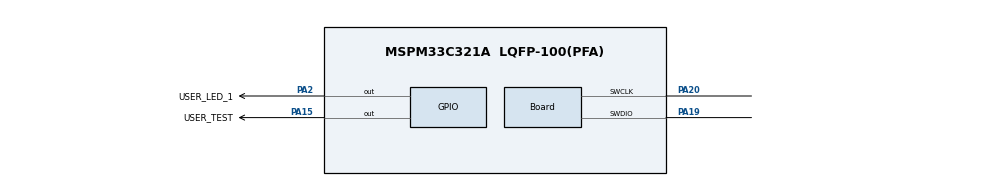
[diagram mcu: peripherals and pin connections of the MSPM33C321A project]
//@cliArgs --device "MSPM33C321A" --package "LQFP-100(PFA)" --part "Default"
//@v2CliArgs --device "MSPM33C321A" --package "LQFP-100(PFA)"
// @cliArgs --board /ti/boards/LP_MSPM33C321A --rtos nortos


/**
 * Import the modules used in this configuration.
 */
const GPIO   = scripting.addModule("/ti/driverlib/GPIO", {}, false);
const GPIO1  = GPIO.addInstance();
const SYSCTL = scripting.addModule("/ti/driverlib/SYSCTL");


/**
 * Write custom configuration values to the imported modules.
 */
GPIO1.$name                                 = "GPIO_LEDS";
GPIO1.associatedPins.create(2);
GPIO1.associatedPins[0].$name               = "USER_LED_1";
GPIO1.associatedPins[0].launchPadShortcut   = "LED2BlueEn";
GPIO1.associatedPins[0].pin.$assign         = "PA2";
GPIO1.associatedPins[1].assignedPort        = "PORTA";
GPIO1.associatedPins[1].$name               = "USER_TEST";
GPIO1.associatedPins[1].assignedPortSegment = "Lower";
GPIO1.associatedPins[1].assignedPin         = "15";
GPIO1.associatedPins[1].hiZ                 = "ENABLE";
GPIO1.associatedPins[1].pin.$assign         = "PA15";

const Board                       = scripting.addModule("/ti/driverlib/Board", {}, false);
Board.peripheral.$assign          = "DEBUGSS";
Board.peripheral.swclkPin.$assign = "PA20";
Board.peripheral.swdioPin.$assign = "PA19";

SYSCTL.forceDefaultClkConfig = true;
SYSCTL.peripheral.$assign    = "SYSCTL";

const ProjectConfig              = scripting.addModule("/ti/project_config/ProjectConfig", {}, false);
ProjectConfig.migrationCondition = true;

ProjectConfig.genLinker  = true;
ProjectConfig.genStartup = true;
ProjectConfig.genOpts    = true;
ProjectConfig.genLibs    = true;
